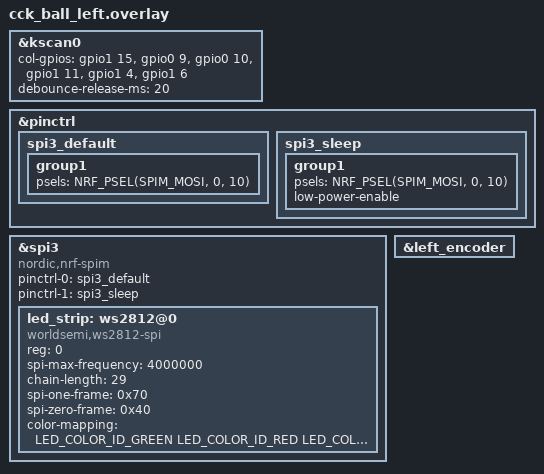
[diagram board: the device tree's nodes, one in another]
/*
 * Copyright (c) 2020 ZMK Contributors
 *
 * SPDX-License-Identifier: MIT
 */

#include "cck_ball.dtsi"

&kscan0 {
	col-gpios
		= <&gpio1 15 GPIO_ACTIVE_HIGH>
        , <&gpio0 9 GPIO_ACTIVE_HIGH>
        , <&gpio0 10 GPIO_ACTIVE_HIGH>
        , <&gpio1 11 GPIO_ACTIVE_HIGH>
        , <&gpio1 4 GPIO_ACTIVE_HIGH>
        , <&gpio1 6 GPIO_ACTIVE_HIGH>
		;

	/* Дребезг свитча KeyF (русская «а») — подтверждён ловцом 2026-08-02:
	 * release -> press той же клавиши за 0.46-0.85 мс при held 0.45-15 мс.
	 * Задвоение рождается из дребезга на РАЗМЫКАНИИ (release -> press ->
	 * release), поэтому гасим именно release: 20 мс это всё ещё 50 нажатий/с.
	 * debounce-press-ms НЕ трогаем (дефолт 5): его увеличение отбрасывает
	 * короткие касания и усилило бы пропуски, которых у этого свитча и так
	 * хватает. Паллиатив до чистки/замены свитча, не лечение. */
	debounce-release-ms = <20>;
};

//RGB bus

&pinctrl {
    spi3_default: spi3_default {
        group1 {
            psels = <NRF_PSEL(SPIM_MOSI, 0, 10)>;
        };
    };

    spi3_sleep: spi3_sleep {
        group1 {
            psels = <NRF_PSEL(SPIM_MOSI, 0, 10)>;
            low-power-enable;
        };
    };
};

&spi3 {
    compatible = "nordic,nrf-spim";
    status = "okay";

    pinctrl-0 = <&spi3_default>;
    pinctrl-1 = <&spi3_sleep>;
    pinctrl-names = "default", "sleep";

    led_strip: ws2812@0 {
        compatible = "worldsemi,ws2812-spi";

        /* SPI */
        reg = <0>; /* ignored, but necessary for SPI bindings */
        spi-max-frequency = <4000000>;

        /* WS2812 */
        chain-length = <29>; /* number of LEDs */
        spi-one-frame = <0x70>;
        spi-zero-frame = <0x40>;
        color-mapping = <LED_COLOR_ID_GREEN
                         LED_COLOR_ID_RED
                         LED_COLOR_ID_BLUE>;
    };
};

// enable left encoder
&left_encoder {
	status = "okay";
};
